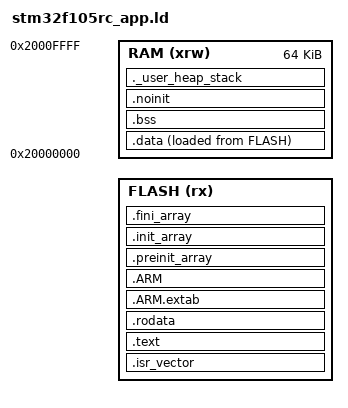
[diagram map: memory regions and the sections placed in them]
/*
 * GCC linker script for Snapmaker (Original) Marlin on STM32F105RC / GD32F105RC.
 * Mirrors stm32f10x_flash.icf (IAR).
 *
 * Flash map (see STM32_Pin_Control.cpp, configuration_store.cpp):
 *   0x08000000  32K  bootloader (NOT part of these sources - never erase it)
 *   0x08008000   6K  bootloader parameters
 *   0x08009800 128K  this application            <- APP_BASE
 *   0x08029800   4K  Marlin settings (EEPROM emulation, FLASH_BASE_ADDR)
 *
 * Define STANDALONE=1 in the Makefile to link at 0x08000000 without bootloader.
 */

ENTRY(Reset_Handler)

_Min_Heap_Size  = 0x3000;
_Min_Stack_Size = 0x3000;

MEMORY
{
  FLASH (rx)  : ORIGIN = APP_BASE, LENGTH = APP_SIZE
  RAM   (xrw) : ORIGIN = 0x20000000, LENGTH = 64K
}

_estack = ORIGIN(RAM) + LENGTH(RAM);

SECTIONS
{
  .isr_vector :
  {
    . = ALIGN(4);
    KEEP(*(.isr_vector))
    . = ALIGN(4);
  } >FLASH

  .text :
  {
    . = ALIGN(4);
    *(.text)
    *(.text*)
    *(.glue_7)
    *(.glue_7t)
    *(.eh_frame)
    KEEP (*(.init))
    KEEP (*(.fini))
    . = ALIGN(4);
    _etext = .;
  } >FLASH

  .rodata :
  {
    . = ALIGN(4);
    *(.rodata)
    *(.rodata*)
    . = ALIGN(4);
  } >FLASH

  .ARM.extab : { *(.ARM.extab* .gnu.linkonce.armextab.*) } >FLASH
  .ARM : {
    __exidx_start = .;
    *(.ARM.exidx*)
    __exidx_end = .;
  } >FLASH

  .preinit_array :
  {
    PROVIDE_HIDDEN (__preinit_array_start = .);
    KEEP (*(.preinit_array*))
    PROVIDE_HIDDEN (__preinit_array_end = .);
  } >FLASH
  .init_array :
  {
    PROVIDE_HIDDEN (__init_array_start = .);
    KEEP (*(SORT(.init_array.*)))
    KEEP (*(.init_array*))
    PROVIDE_HIDDEN (__init_array_end = .);
  } >FLASH
  .fini_array :
  {
    PROVIDE_HIDDEN (__fini_array_start = .);
    KEEP (*(SORT(.fini_array.*)))
    KEEP (*(.fini_array*))
    PROVIDE_HIDDEN (__fini_array_end = .);
  } >FLASH

  _sidata = LOADADDR(.data);

  .data :
  {
    . = ALIGN(4);
    _sdata = .;
    *(.data)
    *(.data*)
    . = ALIGN(4);
    _edata = .;
  } >RAM AT> FLASH

  .bss (NOLOAD) :
  {
    . = ALIGN(4);
    _sbss = .;
    __bss_start__ = _sbss;
    *(.bss)
    *(.bss*)
    *(COMMON)
    . = ALIGN(4);
    _ebss = .;
    __bss_end__ = _ebss;
  } >RAM

  .noinit (NOLOAD) : { *(.noinit*) } >RAM

  ._user_heap_stack (NOLOAD) :
  {
    . = ALIGN(8);
    PROVIDE ( end = . );
    PROVIDE ( _end = . );
    . = . + _Min_Heap_Size;
    . = . + _Min_Stack_Size;
    . = ALIGN(8);
  } >RAM

  .ARM.attributes 0 : { *(.ARM.attributes) }
}
